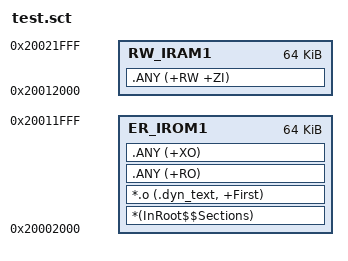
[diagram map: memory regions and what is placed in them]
; *************************************************************
; *** Scatter-Loading Description File generated by uVision ***
; *************************************************************
;分散加载的根本功能是指定程序在存储空间上面的存储分配以及运行空间的分配,所有要有加载域和运行域来分别指定程序存储空间以及程序运行空间
;至少一个加载域、建议两个运行域（一个RO运行域、一个RW+ZI运行域）
LR_IROM1 0x20002000 0x00010000  {    ; 【加载域描述】这段是要告诉链接器，你的程序是存在哪里？我从哪里去找需要执行的代码。
  ER_IROM1 0x20002000 0x00010000  {  ; 【运行域描述】这段是要告诉链接器，你的程序在哪里执行，在ARM Cortex-M系列的绝大多数MCU中加载域以及运行域是在同一个空间上的，即片内Flash。
;   *.o (RESET, +First)    ;异常&中断向量表，+First表示强制放到首地址
   *(InRoot$$Sections)  ;ARM相关库，InRoot$$Sections是ARM库节的链接标号
   *.o (.dyn_text, +First)
   .ANY (+RO)
   .ANY (+XO)
  }
  RW_IRAM1 0x20012000 0x00010000  {  ; RW data
   .ANY (+RW +ZI)
  }
}

